VERSION ""

NS_ :

BS_:

BU_: ECM TCM BCM TPMS ADAS BMS ICM HVAC LIGHT CONN MAINT GPS

VAL_TABLE_ IgnitionState 0 "OFF" 1 "ON" ;
VAL_TABLE_ SeatbeltState 0 "UNFASTENED" 1 "FASTENED" ;
VAL_TABLE_ GearPosition 0 "PARK" 1 "REVERSE" 2 "NEUTRAL" 3 "DRIVE" ;
VAL_TABLE_ HeadlightMode 0 "OFF" 1 "AUTO" 2 "ON" ;
VAL_TABLE_ SeatHeatLevel 0 "OFF" 1 "LOW" 2 "MEDIUM" 3 "HIGH" ;

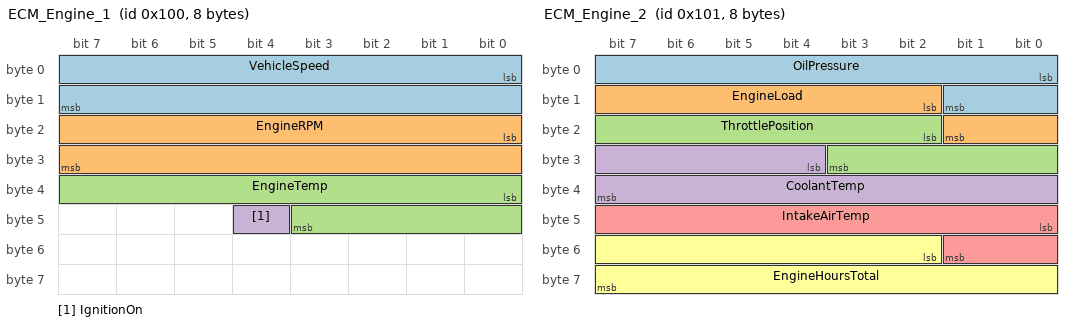
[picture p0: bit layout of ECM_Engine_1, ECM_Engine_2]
BO_ 256 ECM_Engine_1: 8 ECM
 SG_ VehicleSpeed : 0|16@1+ (0.01,0) [0|655.35] "mph" BCM,ADAS,ICM
 SG_ EngineRPM : 16|16@1+ (1,0) [0|8000] "rpm" ICM
 SG_ EngineTemp : 32|12@1+ (0.1,-40) [-40|369.5] "degF" BCM,MAINT
 SG_ IgnitionOn : 44|1@1+ (1,0) [0|1] "" BCM,ICM

BO_ 257 ECM_Engine_2: 8 ECM
 SG_ OilPressure : 0|10@1+ (0.1,0) [0|102.3] "PSI" MAINT
 SG_ EngineLoad : 10|8@1+ (0.5,0) [0|127.5] "%" ICM
 SG_ ThrottlePosition : 18|10@1+ (0.1,0) [0|102.3] "%" ICM
 SG_ CoolantTemp : 28|12@1+ (0.1,-40) [-40|369.5] "degF" MAINT
 SG_ IntakeAirTemp : 40|10@1+ (0.1,-40) [-40|62.3] "degF" ECM
 SG_ EngineHoursTotal : 50|14@1+ (1,0) [0|16383] "hrs" MAINT

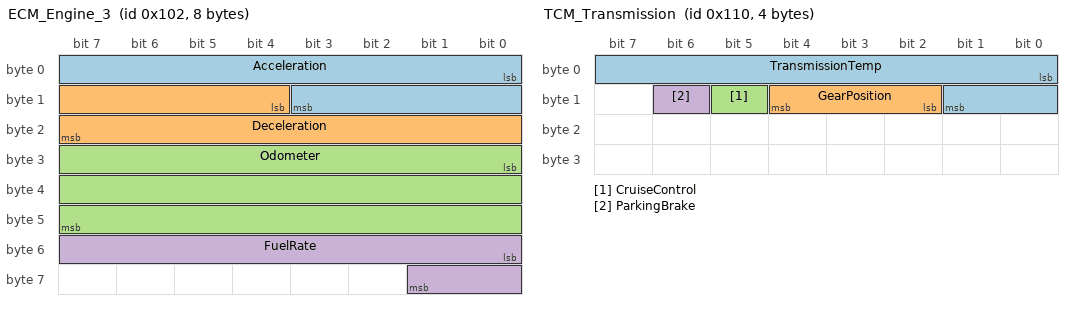
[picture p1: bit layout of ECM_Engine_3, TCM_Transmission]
BO_ 258 ECM_Engine_3: 8 ECM
 SG_ Acceleration : 0|12@1+ (0.01,-20) [-20|20.95] "m/s2" ADAS
 SG_ Deceleration : 12|12@1+ (0.01,-20) [-20|20.95] "m/s2" ADAS
 SG_ Odometer : 24|24@1+ (1,0) [0|16777215] "miles" ICM,MAINT
 SG_ FuelRate : 48|10@1+ (0.05,0) [0|51.15] "L/h" MAINT

BO_ 272 TCM_Transmission: 4 TCM
 SG_ TransmissionTemp : 0|10@1+ (0.5,-40) [-40|471.5] "degF" MAINT
 SG_ GearPosition : 10|3@1+ (1,0) [0|7] "" ICM
 SG_ CruiseControl : 13|1@1+ (1,0) [0|1] "" ICM
 SG_ ParkingBrake : 14|1@1+ (1,0) [0|1] "" ICM

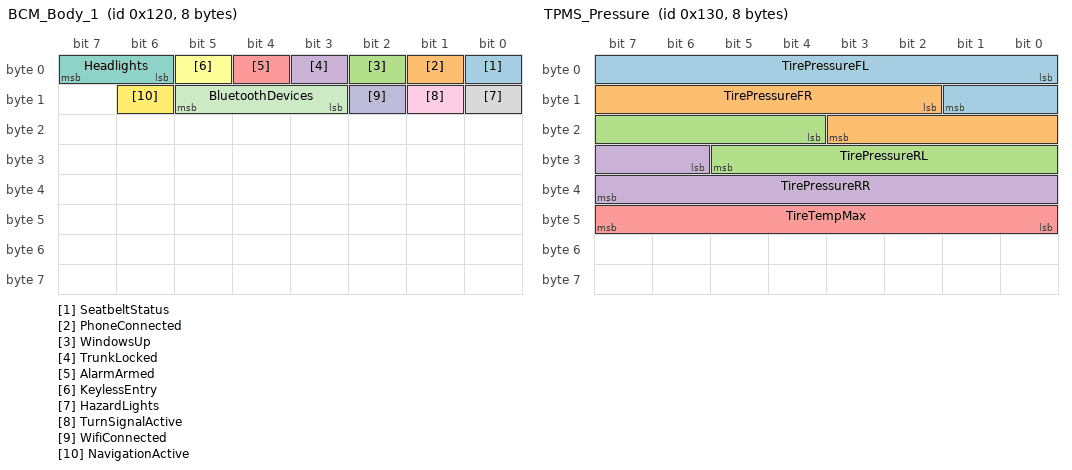
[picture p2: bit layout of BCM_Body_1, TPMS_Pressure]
BO_ 288 BCM_Body_1: 8 BCM
 SG_ SeatbeltStatus : 0|1@1+ (1,0) [0|1] "" ADAS,ICM
 SG_ PhoneConnected : 1|1@1+ (1,0) [0|1] "" ICM
 SG_ WindowsUp : 2|1@1+ (1,0) [0|1] "" ICM
 SG_ TrunkLocked : 3|1@1+ (1,0) [0|1] "" ICM
 SG_ AlarmArmed : 4|1@1+ (1,0) [0|1] "" ICM
 SG_ KeylessEntry : 5|1@1+ (1,0) [0|1] "" ICM
 SG_ Headlights : 6|2@1+ (1,0) [0|2] "" ICM
 SG_ HazardLights : 8|1@1+ (1,0) [0|1] "" ICM
 SG_ TurnSignalActive : 9|1@1+ (1,0) [0|1] "" ICM
 SG_ WifiConnected : 10|1@1+ (1,0) [0|1] "" CONN
 SG_ BluetoothDevices : 11|3@1+ (1,0) [0|7] "" CONN
 SG_ NavigationActive : 14|1@1+ (1,0) [0|1] "" ICM

BO_ 304 TPMS_Pressure: 8 TPMS
 SG_ TirePressureFL : 0|10@1+ (0.1,0) [0|102.3] "PSI" BCM,MAINT
 SG_ TirePressureFR : 10|10@1+ (0.1,0) [0|102.3] "PSI" BCM,MAINT
 SG_ TirePressureRL : 20|10@1+ (0.1,0) [0|102.3] "PSI" BCM,MAINT
 SG_ TirePressureRR : 30|10@1+ (0.1,0) [0|102.3] "PSI" BCM,MAINT
 SG_ TireTempMax : 40|8@1+ (1,0) [0|255] "degF" MAINT

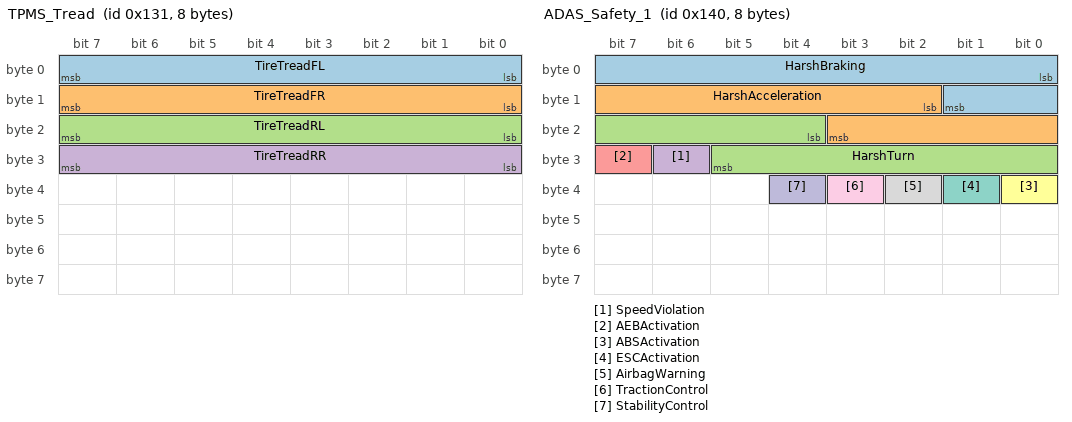
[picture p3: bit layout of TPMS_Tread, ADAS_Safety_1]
BO_ 305 TPMS_Tread: 8 TPMS
 SG_ TireTreadFL : 0|8@1+ (0.1,0) [0|25.5] "mm" MAINT
 SG_ TireTreadFR : 8|8@1+ (0.1,0) [0|25.5] "mm" MAINT
 SG_ TireTreadRL : 16|8@1+ (0.1,0) [0|25.5] "mm" MAINT
 SG_ TireTreadRR : 24|8@1+ (0.1,0) [0|25.5] "mm" MAINT

BO_ 320 ADAS_Safety_1: 8 ADAS
 SG_ HarshBraking : 0|10@1+ (0.001,0) [0|1.023] "g" BCM
 SG_ HarshAcceleration : 10|10@1+ (0.001,0) [0|1.023] "g" BCM
 SG_ HarshTurn : 20|10@1+ (0.1,0) [0|102.3] "deg/s" BCM
 SG_ SpeedViolation : 30|1@1+ (1,0) [0|1] "" BCM,ICM
 SG_ AEBActivation : 31|1@1+ (1,0) [0|1] "" BCM,ICM
 SG_ ABSActivation : 32|1@1+ (1,0) [0|1] "" BCM,ICM
 SG_ ESCActivation : 33|1@1+ (1,0) [0|1] "" BCM,ICM
 SG_ AirbagWarning : 34|1@1+ (1,0) [0|1] "" BCM,ICM
 SG_ TractionControl : 35|1@1+ (1,0) [0|1] "" ICM
 SG_ StabilityControl : 36|1@1+ (1,0) [0|1] "" ICM

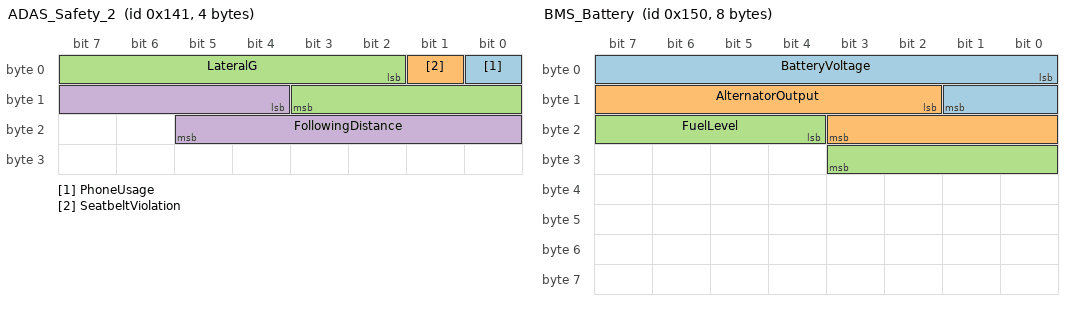
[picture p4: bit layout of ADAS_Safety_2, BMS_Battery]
BO_ 321 ADAS_Safety_2: 4 ADAS
 SG_ PhoneUsage : 0|1@1+ (1,0) [0|1] "" BCM,ICM
 SG_ SeatbeltViolation : 1|1@1+ (1,0) [0|1] "" BCM,ICM
 SG_ LateralG : 2|10@1+ (0.01,-5) [-5|5.23] "g" BCM
 SG_ FollowingDistance : 12|10@1+ (0.1,0) [0|102.3] "m" BCM

BO_ 336 BMS_Battery: 8 BMS
 SG_ BatteryVoltage : 0|10@1+ (0.02,0) [0|20.46] "V" MAINT,ICM
 SG_ AlternatorOutput : 10|10@1+ (0.02,0) [0|20.46] "V" MAINT
 SG_ FuelLevel : 20|8@1+ (0.5,0) [0|127.5] "%" ICM,MAINT

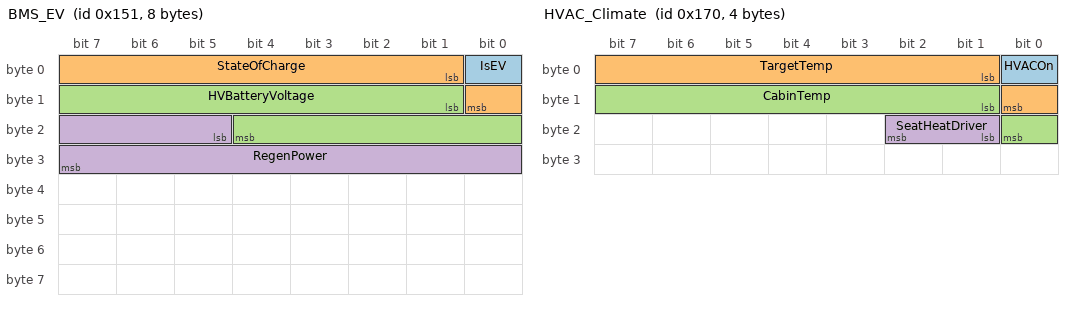
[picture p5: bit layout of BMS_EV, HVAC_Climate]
BO_ 337 BMS_EV: 8 BMS
 SG_ IsEV : 0|1@1+ (1,0) [0|1] "" ICM
 SG_ StateOfCharge : 1|8@1+ (0.5,0) [0|127.5] "%" ICM,MAINT
 SG_ HVBatteryVoltage : 9|12@1+ (0.1,0) [0|409.5] "V" MAINT
 SG_ RegenPower : 21|11@1+ (0.1,-50) [-50|154.7] "kW" ICM

BO_ 352 ICM_Instrument: 4 ICM
 SG_ Heading : 0|12@1+ (0.1,0) [0|409.5] "deg" GPS
 SG_ DTCCodesActive : 12|1@1+ (1,0) [0|1] "" MAINT

BO_ 368 HVAC_Climate: 4 HVAC
 SG_ HVACOn : 0|1@1+ (1,0) [0|1] "" ICM
 SG_ TargetTemp : 1|8@1+ (0.5,40) [40|167.5] "degF" ICM
 SG_ CabinTemp : 9|8@1+ (0.5,40) [40|167.5] "degF" ICM
 SG_ SeatHeatDriver : 17|2@1+ (1,0) [0|3] "" ICM

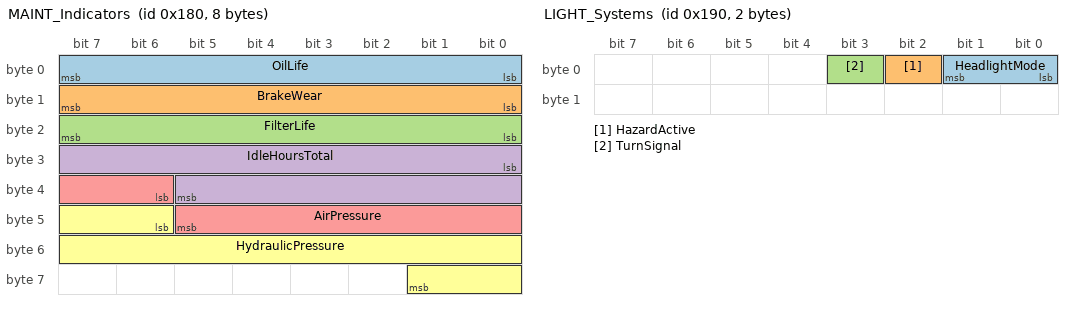
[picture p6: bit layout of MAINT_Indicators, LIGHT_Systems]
BO_ 384 MAINT_Indicators: 8 MAINT
 SG_ OilLife : 0|8@1+ (0.5,0) [0|127.5] "%" ICM
 SG_ BrakeWear : 8|8@1+ (0.5,0) [0|127.5] "%" ICM
 SG_ FilterLife : 16|8@1+ (0.5,0) [0|127.5] "%" ICM
 SG_ IdleHoursTotal : 24|14@1+ (1,0) [0|16383] "hrs" ICM
 SG_ AirPressure : 38|8@1+ (0.5,0) [0|127.5] "PSI" ICM
 SG_ HydraulicPressure : 46|12@1+ (1,0) [0|4095] "PSI" ICM

BO_ 400 LIGHT_Systems: 2 LIGHT
 SG_ HeadlightMode : 0|2@1+ (1,0) [0|2] "" ICM
 SG_ HazardActive : 2|1@1+ (1,0) [0|1] "" ICM
 SG_ TurnSignal : 3|1@1+ (1,0) [0|1] "" ICM

BA_DEF_ SG_ "SignalLongName" STRING ;
BA_DEF_ BO_ "GenMsgCycleTime" INT 0 10000;

BA_DEF_DEF_ "SignalLongName" "";
BA_DEF_DEF_ "GenMsgCycleTime" 0;

BA_ "GenMsgCycleTime" BO_ 256 100;
BA_ "GenMsgCycleTime" BO_ 257 500;
BA_ "GenMsgCycleTime" BO_ 258 100;
BA_ "GenMsgCycleTime" BO_ 272 200;
BA_ "GenMsgCycleTime" BO_ 288 500;
BA_ "GenMsgCycleTime" BO_ 304 1000;
BA_ "GenMsgCycleTime" BO_ 305 5000;
BA_ "GenMsgCycleTime" BO_ 320 100;
BA_ "GenMsgCycleTime" BO_ 321 100;
BA_ "GenMsgCycleTime" BO_ 336 1000;
BA_ "GenMsgCycleTime" BO_ 337 1000;
BA_ "GenMsgCycleTime" BO_ 352 200;
BA_ "GenMsgCycleTime" BO_ 368 2000;
BA_ "GenMsgCycleTime" BO_ 384 5000;
BA_ "GenMsgCycleTime" BO_ 400 500;

BA_ "SignalLongName" SG_ 256 VehicleSpeed "Vehicle.Speed";
BA_ "SignalLongName" SG_ 256 EngineRPM "Vehicle.Powertrain.Engine.RPM";
BA_ "SignalLongName" SG_ 256 EngineTemp "Vehicle.Powertrain.Engine.Temperature";
BA_ "SignalLongName" SG_ 256 IgnitionOn "Vehicle.Powertrain.IgnitionOn";
BA_ "SignalLongName" SG_ 257 OilPressure "Vehicle.Powertrain.Engine.OilPressure";
BA_ "SignalLongName" SG_ 257 EngineLoad "Vehicle.Powertrain.Engine.Load";
BA_ "SignalLongName" SG_ 257 ThrottlePosition "Vehicle.Powertrain.Engine.ThrottlePosition";
BA_ "SignalLongName" SG_ 257 CoolantTemp "Vehicle.Powertrain.Engine.CoolantTemperature";
BA_ "SignalLongName" SG_ 257 IntakeAirTemp "Vehicle.Powertrain.Engine.IntakeAirTemperature";
BA_ "SignalLongName" SG_ 257 EngineHoursTotal "Vehicle.Powertrain.Engine.HoursTotal";
BA_ "SignalLongName" SG_ 258 Acceleration "Vehicle.Acceleration";
BA_ "SignalLongName" SG_ 258 Deceleration "Vehicle.Deceleration";
BA_ "SignalLongName" SG_ 258 Odometer "Vehicle.Odometer";
BA_ "SignalLongName" SG_ 258 FuelRate "Vehicle.Powertrain.FuelSystem.FuelRate";
BA_ "SignalLongName" SG_ 272 TransmissionTemp "Vehicle.Powertrain.Transmission.Temperature";
BA_ "SignalLongName" SG_ 272 GearPosition "Vehicle.Powertrain.Transmission.GearPosition";
BA_ "SignalLongName" SG_ 272 CruiseControl "Vehicle.ADAS.CruiseControl.Active";
BA_ "SignalLongName" SG_ 272 ParkingBrake "Vehicle.Chassis.ParkingBrake.Active";
BA_ "SignalLongName" SG_ 288 SeatbeltStatus "Vehicle.Cabin.Seatbelt.Driver.Fastened";
BA_ "SignalLongName" SG_ 288 PhoneConnected "Vehicle.Cabin.Infotainment.PhoneConnected";
BA_ "SignalLongName" SG_ 288 WindowsUp "Vehicle.Cabin.Windows.AllClosed";
BA_ "SignalLongName" SG_ 288 TrunkLocked "Vehicle.Body.Trunk.Locked";
BA_ "SignalLongName" SG_ 288 AlarmArmed "Vehicle.Body.Alarm.Armed";
BA_ "SignalLongName" SG_ 288 KeylessEntry "Vehicle.Body.KeylessEntry.Proximity";
BA_ "SignalLongName" SG_ 288 Headlights "Vehicle.Body.Lights.Headlights.Mode";
BA_ "SignalLongName" SG_ 288 HazardLights "Vehicle.Body.Lights.Hazard.Active";
BA_ "SignalLongName" SG_ 288 TurnSignalActive "Vehicle.Body.Lights.TurnSignal.Active";
BA_ "SignalLongName" SG_ 288 WifiConnected "Vehicle.Connectivity.WiFi.Connected";
BA_ "SignalLongName" SG_ 288 BluetoothDevices "Vehicle.Connectivity.Bluetooth.DeviceCount";
BA_ "SignalLongName" SG_ 288 NavigationActive "Vehicle.Cabin.Infotainment.Navigation.Active";
BA_ "SignalLongName" SG_ 304 TirePressureFL "Vehicle.Chassis.Axle.Row1.Wheel.Left.Tire.Pressure";
BA_ "SignalLongName" SG_ 304 TirePressureFR "Vehicle.Chassis.Axle.Row1.Wheel.Right.Tire.Pressure";
BA_ "SignalLongName" SG_ 304 TirePressureRL "Vehicle.Chassis.Axle.Row2.Wheel.Left.Tire.Pressure";
BA_ "SignalLongName" SG_ 304 TirePressureRR "Vehicle.Chassis.Axle.Row2.Wheel.Right.Tire.Pressure";
BA_ "SignalLongName" SG_ 304 TireTempMax "Vehicle.Chassis.Tire.TemperatureMax";
BA_ "SignalLongName" SG_ 305 TireTreadFL "Vehicle.Chassis.Axle.Row1.Wheel.Left.Tire.TreadDepth";
BA_ "SignalLongName" SG_ 305 TireTreadFR "Vehicle.Chassis.Axle.Row1.Wheel.Right.Tire.TreadDepth";
BA_ "SignalLongName" SG_ 305 TireTreadRL "Vehicle.Chassis.Axle.Row2.Wheel.Left.Tire.TreadDepth";
BA_ "SignalLongName" SG_ 305 TireTreadRR "Vehicle.Chassis.Axle.Row2.Wheel.Right.Tire.TreadDepth";
BA_ "SignalLongName" SG_ 320 HarshBraking "Vehicle.ADAS.Safety.HarshBraking";
BA_ "SignalLongName" SG_ 320 HarshAcceleration "Vehicle.ADAS.Safety.HarshAcceleration";
BA_ "SignalLongName" SG_ 320 HarshTurn "Vehicle.ADAS.Safety.HarshTurn";
BA_ "SignalLongName" SG_ 320 SpeedViolation "Vehicle.ADAS.Safety.SpeedViolation";
BA_ "SignalLongName" SG_ 320 AEBActivation "Vehicle.ADAS.AEB.Active";
BA_ "SignalLongName" SG_ 320 ABSActivation "Vehicle.ADAS.ABS.Active";
BA_ "SignalLongName" SG_ 320 ESCActivation "Vehicle.ADAS.ESC.Active";
BA_ "SignalLongName" SG_ 320 AirbagWarning "Vehicle.Safety.Airbag.Warning";
BA_ "SignalLongName" SG_ 320 TractionControl "Vehicle.ADAS.TractionControl.Active";
BA_ "SignalLongName" SG_ 320 StabilityControl "Vehicle.ADAS.StabilityControl.Active";
BA_ "SignalLongName" SG_ 321 PhoneUsage "Vehicle.Safety.Driver.PhoneUsage";
BA_ "SignalLongName" SG_ 321 SeatbeltViolation "Vehicle.Safety.Driver.SeatbeltViolation";
BA_ "SignalLongName" SG_ 321 LateralG "Vehicle.Acceleration.Lateral";
BA_ "SignalLongName" SG_ 321 FollowingDistance "Vehicle.ADAS.FollowingDistance";
BA_ "SignalLongName" SG_ 336 BatteryVoltage "Vehicle.Powertrain.Battery.Voltage";
BA_ "SignalLongName" SG_ 336 AlternatorOutput "Vehicle.Powertrain.Alternator.Voltage";
BA_ "SignalLongName" SG_ 336 FuelLevel "Vehicle.Powertrain.FuelSystem.Level";
BA_ "SignalLongName" SG_ 337 IsEV "Vehicle.Powertrain.Type.IsEV";
BA_ "SignalLongName" SG_ 337 StateOfCharge "Vehicle.Powertrain.Battery.StateOfCharge";
BA_ "SignalLongName" SG_ 337 HVBatteryVoltage "Vehicle.Powertrain.Battery.HVVoltage";
BA_ "SignalLongName" SG_ 337 RegenPower "Vehicle.Powertrain.Battery.RegenPower";
BA_ "SignalLongName" SG_ 352 Heading "Vehicle.Navigation.Heading";
BA_ "SignalLongName" SG_ 352 DTCCodesActive "Vehicle.Diagnostics.DTCActive";
BA_ "SignalLongName" SG_ 368 HVACOn "Vehicle.Cabin.HVAC.Active";
BA_ "SignalLongName" SG_ 368 TargetTemp "Vehicle.Cabin.HVAC.TargetTemperature";
BA_ "SignalLongName" SG_ 368 CabinTemp "Vehicle.Cabin.HVAC.CabinTemperature";
BA_ "SignalLongName" SG_ 368 SeatHeatDriver "Vehicle.Cabin.Seat.Driver.HeatingLevel";
BA_ "SignalLongName" SG_ 384 OilLife "Vehicle.Maintenance.OilLife";
BA_ "SignalLongName" SG_ 384 BrakeWear "Vehicle.Maintenance.BrakeWear";
BA_ "SignalLongName" SG_ 384 FilterLife "Vehicle.Maintenance.FilterLife";
BA_ "SignalLongName" SG_ 384 IdleHoursTotal "Vehicle.Powertrain.Engine.IdleHoursTotal";
BA_ "SignalLongName" SG_ 384 AirPressure "Vehicle.Chassis.Brake.AirPressure";
BA_ "SignalLongName" SG_ 384 HydraulicPressure "Vehicle.Chassis.Brake.HydraulicPressure";

VAL_ 256 IgnitionOn 0 "OFF" 1 "ON" ;
VAL_ 288 SeatbeltStatus 0 "UNFASTENED" 1 "FASTENED" ;
VAL_ 272 GearPosition 0 "PARK" 1 "REVERSE" 2 "NEUTRAL" 3 "DRIVE" ;
VAL_ 288 Headlights 0 "OFF" 1 "AUTO" 2 "ON" ;
VAL_ 368 SeatHeatDriver 0 "OFF" 1 "LOW" 2 "MEDIUM" 3 "HIGH" ;

CM_ BU_ ECM "Engine Control Module - powertrain signals";
CM_ BU_ TCM "Transmission Control Module";
CM_ BU_ BCM "Body Control Module - body electronics";
CM_ BU_ TPMS "Tire Pressure Monitoring System";
CM_ BU_ ADAS "Advanced Driver Assistance Systems";
CM_ BU_ BMS "Battery Management System";
CM_ BU_ ICM "Instrument Cluster Module";
CM_ BU_ HVAC "Climate Control Module";
CM_ BU_ LIGHT "Lighting Control Module";
CM_ BU_ CONN "Connectivity Module - WiFi/BT";
CM_ BU_ MAINT "Maintenance Monitoring Module";
CM_ BU_ GPS "GPS/Navigation Module";

CM_ BO_ 256 "Primary engine data - speed, RPM, temp, ignition (100ms cycle)";
CM_ BO_ 257 "Secondary engine data - oil, load, throttle, coolant (500ms cycle)";
CM_ BO_ 258 "Vehicle dynamics - accel, decel, odometer, fuel rate (100ms cycle)";
CM_ BO_ 272 "Transmission status and driver controls (200ms cycle)";
CM_ BO_ 288 "Body electronics - seatbelt, locks, windows, connectivity (500ms cycle)";
CM_ BO_ 304 "Tire pressure monitoring - all 4 wheels + temp (1000ms cycle)";
CM_ BO_ 305 "Tire tread depth monitoring - all 4 wheels (5000ms cycle)";
CM_ BO_ 320 "ADAS safety events - braking, acceleration, stability (100ms cycle)";
CM_ BO_ 321 "ADAS driver monitoring - phone, seatbelt, following (100ms cycle)";
CM_ BO_ 336 "12V battery and fuel system (1000ms cycle)";
CM_ BO_ 337 "EV/HV battery system - SOC, voltage, regen (1000ms cycle)";
CM_ BO_ 352 "Instrument cluster - heading, diagnostics (200ms cycle)";
CM_ BO_ 368 "HVAC climate control (2000ms cycle)";
CM_ BO_ 384 "Maintenance indicators - oil, brake, filter life (5000ms cycle)";
CM_ BO_ 400 "Exterior lighting systems (500ms cycle)";
